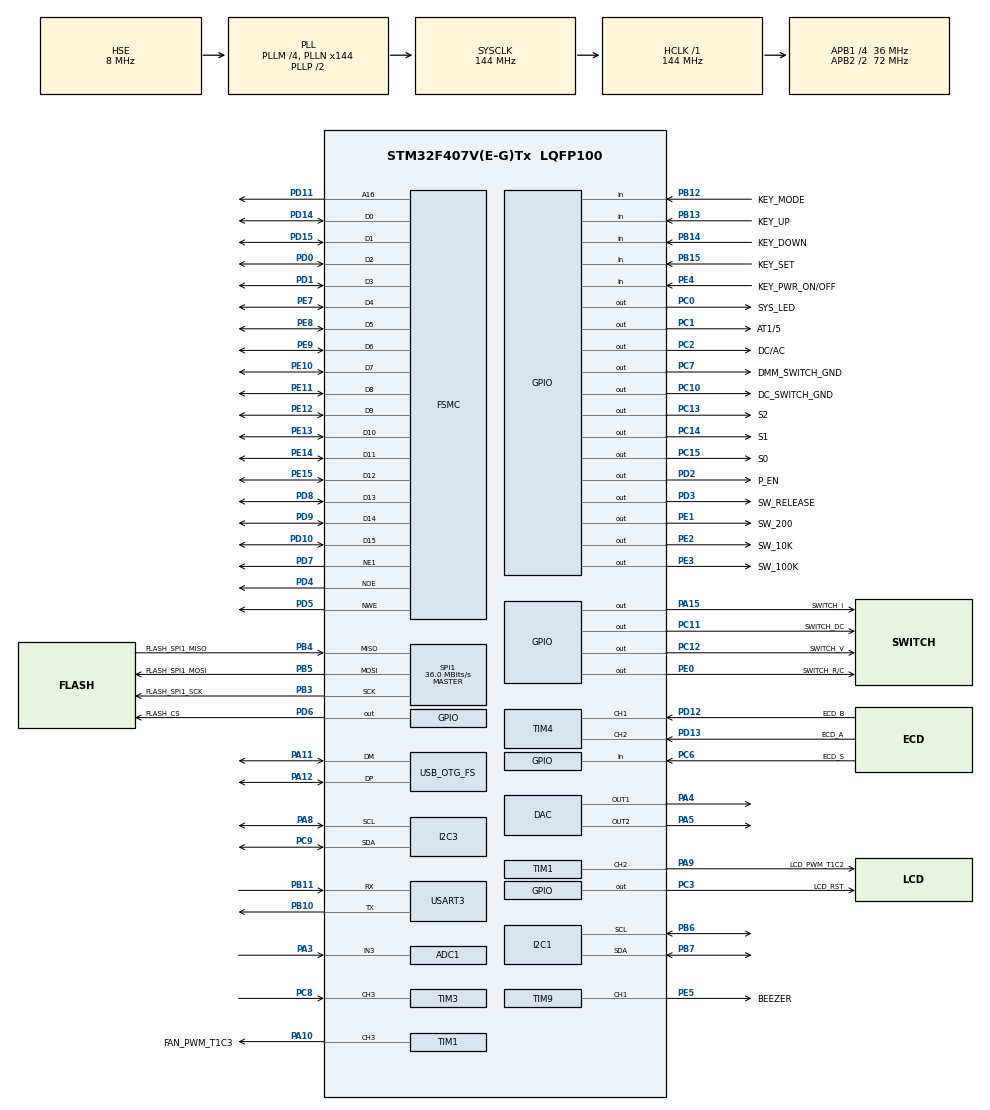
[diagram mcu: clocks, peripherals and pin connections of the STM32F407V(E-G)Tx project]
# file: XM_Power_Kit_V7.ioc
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ADC1.Channel-4\#ChannelRegularConversion=ADC_CHANNEL_3
ADC1.DMAContinuousRequests=ENABLE
ADC1.EOCSelection=ADC_EOC_SINGLE_CONV
ADC1.ExternalTrigConv=ADC_EXTERNALTRIGCONV_T8_TRGO
ADC1.NbrOfConversion=1
ADC1.NbrOfConversionFlag=1
ADC1.Rank-4\#ChannelRegularConversion=1
ADC1.Resolution=ADC_RESOLUTION_8B
ADC1.SamplingTime-4\#ChannelRegularConversion=ADC_SAMPLETIME_3CYCLES
ADC1.ScanConvMode=DISABLE
ADC1.master=1
DAC.DAC_Trigger=DAC_TRIGGER_T7_TRGO
DAC.WaveGeneration=DISABLE
Dma.ADC1.3.Direction=DMA_PERIPH_TO_MEMORY
Dma.ADC1.3.FIFOMode=DMA_FIFOMODE_DISABLE
Dma.ADC1.3.Instance=DMA2_Stream4
Dma.ADC1.3.MemDataAlignment=DMA_MDATAALIGN_BYTE
Dma.ADC1.3.MemInc=DMA_MINC_ENABLE
Dma.ADC1.3.Mode=DMA_CIRCULAR
Dma.ADC1.3.PeriphDataAlignment=DMA_PDATAALIGN_BYTE
Dma.ADC1.3.PeriphInc=DMA_PINC_DISABLE
Dma.ADC1.3.Priority=DMA_PRIORITY_HIGH
Dma.DAC1.4.Direction=DMA_MEMORY_TO_PERIPH
Dma.DAC1.4.FIFOMode=DMA_FIFOMODE_DISABLE
Dma.DAC1.4.Instance=DMA1_Stream5
Dma.DAC1.4.MemDataAlignment=DMA_MDATAALIGN_HALFWORD
Dma.DAC1.4.MemInc=DMA_MINC_ENABLE
Dma.DAC1.4.Mode=DMA_CIRCULAR
Dma.DAC1.4.PeriphDataAlignment=DMA_PDATAALIGN_HALFWORD
Dma.DAC1.4.PeriphInc=DMA_PINC_DISABLE
Dma.DAC1.4.Priority=DMA_PRIORITY_MEDIUM
Dma.MEMTOMEM.2.Direction=DMA_MEMORY_TO_MEMORY
Dma.MEMTOMEM.2.FIFOMode=DMA_FIFOMODE_ENABLE
Dma.MEMTOMEM.2.FIFOThreshold=DMA_FIFO_THRESHOLD_FULL
Dma.MEMTOMEM.2.Instance=DMA2_Stream6
Dma.MEMTOMEM.2.MemBurst=DMA_MBURST_SINGLE
Dma.MEMTOMEM.2.MemDataAlignment=DMA_MDATAALIGN_HALFWORD
Dma.MEMTOMEM.2.MemInc=DMA_MINC_ENABLE
Dma.MEMTOMEM.2.Mode=DMA_NORMAL
Dma.MEMTOMEM.2.PeriphBurst=DMA_PBURST_SINGLE
Dma.MEMTOMEM.2.PeriphDataAlignment=DMA_PDATAALIGN_HALFWORD
Dma.MEMTOMEM.2.PeriphInc=DMA_PINC_ENABLE
Dma.MEMTOMEM.2.Priority=DMA_PRIORITY_LOW
Dma.Request0=SPI1_RX
Dma.Request1=SPI1_TX
Dma.Request2=MEMTOMEM
Dma.Request3=ADC1
Dma.Request4=DAC1
Dma.SPI1_RX.0.Direction=DMA_PERIPH_TO_MEMORY
Dma.SPI1_RX.0.FIFOMode=DMA_FIFOMODE_DISABLE
Dma.SPI1_RX.0.Instance=DMA2_Stream0
Dma.SPI1_RX.0.MemDataAlignment=DMA_MDATAALIGN_BYTE
Dma.SPI1_RX.0.MemInc=DMA_MINC_ENABLE
Dma.SPI1_RX.0.Mode=DMA_NORMAL
Dma.SPI1_RX.0.PeriphDataAlignment=DMA_PDATAALIGN_BYTE
Dma.SPI1_RX.0.PeriphInc=DMA_PINC_DISABLE
Dma.SPI1_RX.0.Priority=DMA_PRIORITY_MEDIUM
Dma.SPI1_TX.1.Direction=DMA_MEMORY_TO_PERIPH
Dma.SPI1_TX.1.FIFOMode=DMA_FIFOMODE_DISABLE
Dma.SPI1_TX.1.Instance=DMA2_Stream3
Dma.SPI1_TX.1.MemDataAlignment=DMA_MDATAALIGN_BYTE
Dma.SPI1_TX.1.MemInc=DMA_MINC_ENABLE
Dma.SPI1_TX.1.Mode=DMA_NORMAL
Dma.SPI1_TX.1.PeriphDataAlignment=DMA_PDATAALIGN_BYTE
Dma.SPI1_TX.1.PeriphInc=DMA_PINC_DISABLE
Dma.SPI1_TX.1.Priority=DMA_PRIORITY_MEDIUM
FREERTOS.BinarySemaphores01=FLASH_TX_Cplt_Sem,Dynamic,NULL,Depleted;FLASH_RX_Cplt_Sem,Dynamic,NULL,Depleted;LCD_DMA_Cplt_Sem,Dynamic,NULL,Depleted
FREERTOS.INCLUDE_uxTaskGetStackHighWaterMark2=1
FREERTOS.INCLUDE_xTaskGetHandle=1
FREERTOS.Mutexes01=IIC1_Mutex,Dynamic,NULL,Available;IIC3_Mutex,Dynamic,NULL,Available;Flash_Mutex,Dynamic,NULL,Available
FREERTOS.Queues01=AppSwitchQueue,1,AppListType,0,Dynamic,NULL,NULL;LcdMsgQueue,48,refresh_msg_t*,0,Dynamic,NULL,NULL;KeyEventQueue,8,KeyEventMsg_t,0,Dynamic,NULL,NULL;BeezerQueue,8,uint16_t,0,Dynamic,NULL,NULL;SerialReqQueue,3,ProtoFrame_t,0,Dynamic,NULL,NULL
FREERTOS.Tasks01=InitTask,55,384,Start_InitTask,As weak,NULL,Dynamic,NULL,NULL;SensorTask,48,192,Start_SensorTask,As external,NULL,Dynamic,NULL,NULL;LcdFlushTask,41,512,Start_LcdFlushTask,As external,NULL,Dynamic,NULL,NULL;PageSelectTask,40,512,Start_PageSelectTask,As external,NULL,Dynamic,NULL,NULL;LvglCoreTask,24,768,Start_LvglCoreTask,As external,NULL,Dynamic,NULL,NULL;DpsCoreTask,24,512,Start_DpsCoreTask,As external,NULL,Dynamic,NULL,NULL;IndevDetectTask,28,128,Start_IndevDetectTask,As external,NULL,Dynamic,NULL,NULL;PIDTask,25,256,Start_PIDTask,As external,NULL,Dynamic,NULL,NULL;CalibrateTask,24,512,Start_CalibrateTask,As external,NULL,Dynamic,NULL,NULL;AwgTask,24,256,Start_AwgTask,As external,NULL,Dynamic,NULL,NULL;DmmCoreTask,24,512,Start_DmmCoreTask,As external,NULL,Dynamic,NULL,NULL;DsoCoreTask,24,512,Start_DsoCoreTask,As external,NULL,Dynamic,NULL,NULL;UserCoreTask,24,512,Start_UserCoreTask,As external,NULL,Dynamic,NULL,NULL;SerialCoreTask,49,384,Start_SerialCoreTask,As external,NULL,Dynamic,NULL,NULL
FREERTOS.configCHECK_FOR_STACK_OVERFLOW=2
FREERTOS.configENABLE_FPU=1
FREERTOS.configGENERATE_RUN_TIME_STATS=1
FREERTOS.configRECORD_STACK_HIGH_ADDRESS=1
FREERTOS.configTOTAL_HEAP_SIZE=32768
FSMC.AddressSetupTime1=5
FSMC.BusTurnAroundDuration1=15
FSMC.DataSetupTime1=5
FSMC.ExtendedMode1=FSMC_EXTENDED_MODE_DISABLE
I2C1.I2C_Mode=I2C_Fast
I2C3.I2C_Mode=I2C_Fast
Mcu.Family=STM32F4
Mcu.Name=STM32F407V(E-G)Tx
Mcu.Package=LQFP100
NVIC.DMA2_Stream0_IRQn=true\:8\:0\:true\:false\:true\:true\:false\:true\:true
NVIC.DMA2_Stream3_IRQn=true\:8\:0\:true\:false\:true\:true\:false\:true\:true
NVIC.DMA2_Stream4_IRQn=true\:5\:0\:false\:false\:true\:true\:true\:true\:true
NVIC.DMA2_Stream6_IRQn=true\:7\:0\:true\:false\:true\:false\:true\:true\:true
NVIC.OTG_FS_IRQn=true\:10\:0\:true\:false\:true\:true\:false\:true\:true
NVIC.PriorityGroup=NVIC_PRIORITYGROUP_4
NVIC.TIM1_TRG_COM_TIM11_IRQn=true\:5\:0\:false\:false\:true\:true\:true\:true\:true
NVIC.TIM3_IRQn=true\:5\:0\:false\:false\:true\:true\:true\:true\:true
NVIC.TIM6_DAC_IRQn=true\:15\:0\:false\:false\:true\:false\:false\:true\:true
NVIC.TimeBase=TIM6_DAC_IRQn
NVIC.TimeBaseIP=TIM6
PA10.GPIO_Label=FAN_PWM_T1C3
PA10.Signal=S_TIM1_CH3
PA11.Mode=Device_Only
PA11.Signal=USB_OTG_FS_DM
PA12.Mode=Device_Only
PA12.Signal=USB_OTG_FS_DP
PA13.Mode=Serial_Wire
PA13.Signal=SYS_JTMS-SWDIO
PA14.Mode=Serial_Wire
PA14.Signal=SYS_JTCK-SWCLK
PA15.GPIO_Label=SWITCH_I
PA15.Signal=GPIO_Output
PA3.Signal=ADCx_IN3
PA4.Signal=COMP_DAC1_group
PA5.Signal=COMP_DAC2_group
PA8.Mode=I2C
PA8.Signal=I2C3_SCL
PA9.GPIO_Label=LCD_PWM_T1C2
PA9.Signal=S_TIM1_CH2
PB10.Mode=Asynchronous
PB10.Signal=USART3_TX
PB11.Mode=Asynchronous
PB11.Signal=USART3_RX
PB12.GPIO_Label=KEY_MODE
PB12.Signal=GPIO_Input
PB13.GPIO_Label=KEY_UP
PB13.Signal=GPIO_Input
PB14.GPIO_Label=KEY_DOWN
PB14.Signal=GPIO_Input
PB15.GPIO_Label=KEY_SET
PB15.Signal=GPIO_Input
PB3.GPIO_Label=FLASH_SPI1_SCK
PB3.Mode=Full_Duplex_Master
PB3.Signal=SPI1_SCK
PB4.GPIO_Label=FLASH_SPI1_MISO
PB4.Mode=Full_Duplex_Master
PB4.Signal=SPI1_MISO
PB5.GPIO_Label=FLASH_SPI1_MOSI
PB5.Mode=Full_Duplex_Master
PB5.Signal=SPI1_MOSI
PB6.Mode=I2C
PB6.Signal=I2C1_SCL
PB7.Mode=I2C
PB7.Signal=I2C1_SDA
PC0.GPIO_Label=SYS_LED
PC0.PinState=GPIO_PIN_SET
PC0.Signal=GPIO_Output
PC1.GPIO_Label=AT1/5
PC1.Signal=GPIO_Output
PC10.GPIO_Label=DC_SWITCH_GND
PC10.Signal=GPIO_Output
PC11.GPIO_Label=SWITCH_DC
PC11.PinState=GPIO_PIN_SET
PC11.Signal=GPIO_Output
PC12.GPIO_Label=SWITCH_V
PC12.Signal=GPIO_Output
PC13-ANTI_TAMP.GPIO_Label=S2
PC13-ANTI_TAMP.PinState=GPIO_PIN_SET
PC13-ANTI_TAMP.Signal=GPIO_Output
PC14-OSC32_IN.GPIO_Label=S1
PC14-OSC32_IN.Signal=GPIO_Output
PC15-OSC32_OUT.GPIO_Label=S0
PC15-OSC32_OUT.Signal=GPIO_Output
PC2.GPIO_Label=DC/AC
PC2.PinState=GPIO_PIN_SET
PC2.Signal=GPIO_Output
PC3.GPIO_Label=LCD_RST
PC3.Signal=GPIO_Output
PC6.GPIO_Label=ECD_S
PC6.Signal=GPIO_Input
PC7.GPIO_Label=DMM_SWITCH_GND
PC7.Signal=GPIO_Output
PC8.Signal=S_TIM3_CH3
PC9.Mode=I2C
PC9.Signal=I2C3_SDA
PD0.Mode=16b-d1
PD0.Signal=FSMC_D2
PD1.Mode=16b-d1
PD1.Signal=FSMC_D3
PD10.Mode=16b-d1
PD10.Signal=FSMC_D15
PD11.Mode=A16_1
PD11.Signal=FSMC_A16
PD12.GPIO_Label=ECD_B
PD12.Signal=S_TIM4_CH1
PD13.GPIO_Label=ECD_A
PD13.Signal=S_TIM4_CH2
PD14.Mode=16b-d1
PD14.Signal=FSMC_D0
PD15.Mode=16b-d1
PD15.Signal=FSMC_D1
PD2.GPIO_Label=P_EN
PD2.Signal=GPIO_Output
PD3.GPIO_Label=SW_RELEASE
PD3.Signal=GPIO_Output
PD4.Mode=Lcd1
PD4.Signal=FSMC_NOE
PD5.Mode=Lcd1
PD5.Signal=FSMC_NWE
PD6.GPIO_Label=FLASH_CS
PD6.PinState=GPIO_PIN_SET
PD6.Signal=GPIO_Output
PD7.Mode=NorPsramChipSelect1_1
PD7.Signal=FSMC_NE1
PD8.Mode=16b-d1
PD8.Signal=FSMC_D13
PD9.Mode=16b-d1
PD9.Signal=FSMC_D14
PE0.GPIO_Label=SWITCH_R/C
PE0.Signal=GPIO_Output
PE1.GPIO_Label=SW_200
PE1.PinState=GPIO_PIN_SET
PE1.Signal=GPIO_Output
PE10.Mode=16b-d1
PE10.Signal=FSMC_D7
PE11.Mode=16b-d1
PE11.Signal=FSMC_D8
PE12.Mode=16b-d1
PE12.Signal=FSMC_D9
PE13.Mode=16b-d1
PE13.Signal=FSMC_D10
PE14.Mode=16b-d1
PE14.Signal=FSMC_D11
PE15.Mode=16b-d1
PE15.Signal=FSMC_D12
PE2.GPIO_Label=SW_10K
PE2.PinState=GPIO_PIN_SET
PE2.Signal=GPIO_Output
PE3.GPIO_Label=SW_100K
PE3.PinState=GPIO_PIN_SET
PE3.Signal=GPIO_Output
PE4.GPIO_Label=KEY_PWR_ON/OFF
PE4.Signal=GPIO_Input
PE5.GPIO_Label=BEEZER
PE5.Signal=S_TIM9_CH1
PE7.Mode=16b-d1
PE7.Signal=FSMC_D4
PE8.Mode=16b-d1
PE8.Signal=FSMC_D5
PE9.Mode=16b-d1
PE9.Signal=FSMC_D6
PH0-OSC_IN.Mode=HSE-External-Oscillator
PH0-OSC_IN.Signal=RCC_OSC_IN
PH1-OSC_OUT.Mode=HSE-External-Oscillator
PH1-OSC_OUT.Signal=RCC_OSC_OUT
ProjectManager.HeapSize=0x1800
ProjectManager.StackSize=0x1000
ProjectManager.TargetToolchain=CMake
RCC.48MHZClocksFreq_Value=48000000
RCC.AHBFreq_Value=144000000
RCC.APB1CLKDivider=RCC_HCLK_DIV4
RCC.APB1Freq_Value=36000000
RCC.APB1TimFreq_Value=72000000
RCC.APB2CLKDivider=RCC_HCLK_DIV2
RCC.APB2Freq_Value=72000000
RCC.APB2TimFreq_Value=144000000
RCC.CortexFreq_Value=144000000
RCC.HCLKFreq_Value=144000000
RCC.HSE_VALUE=8000000
RCC.HSI_VALUE=16000000
RCC.LSE_VALUE=32768
RCC.PLLM=4
RCC.PLLN=144
RCC.PLLQ=6
RCC.SYSCLKFreq_VALUE=144000000
RCC.SYSCLKSource=RCC_SYSCLKSOURCE_PLLCLK
RCC.VCOOutputFreq_Value=288000000
SH.ADCx_IN3.0=ADC1_IN3,IN3
SH.COMP_DAC1_group.0=DAC_OUT1,DAC_OUT1
SH.COMP_DAC2_group.0=DAC_OUT2,DAC_OUT2
SH.S_TIM1_CH2.0=TIM1_CH2,PWM Generation2 CH2
SH.S_TIM1_CH3.0=TIM1_CH3,PWM Generation3 CH3
SH.S_TIM3_CH3.0=TIM3_CH3,Input_Capture3_from_TI3
SH.S_TIM4_CH1.0=TIM4_CH1,Encoder_Interface
SH.S_TIM4_CH2.0=TIM4_CH2,Encoder_Interface
SH.S_TIM9_CH1.0=TIM9_CH1,PWM Generation1 CH1
SPI1.BaudRatePrescaler=SPI_BAUDRATEPRESCALER_2
SPI1.CalculateBaudRate=36.0 MBits/s
SPI1.Direction=SPI_DIRECTION_2LINES
SPI1.Mode=SPI_MODE_MASTER
SPI1.VirtualType=VM_MASTER
TIM1.Channel-PWM\ Generation2\ CH2=TIM_CHANNEL_2
TIM1.Channel-PWM\ Generation3\ CH3=TIM_CHANNEL_3
TIM1.OCFastMode_PWM-PWM\ Generation3\ CH3=TIM_OCFAST_ENABLE
TIM1.Period=1999
TIM1.Prescaler=143
TIM1.Pulse-PWM\ Generation2\ CH2=4999
TIM1.Pulse-PWM\ Generation3\ CH3=0
TIM3.Channel-Input_Capture3_from_TI3=TIM_CHANNEL_3
TIM3.ICFilter_CH3=4
TIM4.EncoderMode=TIM_ENCODERMODE_TI12
TIM4.IC1Filter=3
TIM4.IC1Prescaler=TIM_ICPSC_DIV2
TIM4.IC2Filter=3
TIM4.IC2Prescaler=TIM_ICPSC_DIV2
TIM7.TIM_MasterOutputTrigger=TIM_TRGO_UPDATE
TIM8.Period=15 - 1
TIM8.Prescaler=150 - 1
TIM8.TIM_MasterOutputTrigger=TIM_TRGO_UPDATE
TIM9.Channel-PWM\ Generation1\ CH1=TIM_CHANNEL_1
TIM9.Period=99
TIM9.Prescaler=359
TIM9.Pulse-PWM\ Generation1\ CH1=49
USART3.VirtualMode=VM_ASYNC
USB_DEVICE.APP_RX_DATA_SIZE-CDC_FS=512
USB_DEVICE.APP_TX_DATA_SIZE-CDC_FS=512
USB_DEVICE.CLASS_NAME_FS=CDC
USB_DEVICE.VirtualMode-CDC_FS=Cdc
USB_DEVICE.VirtualModeFS=Cdc_FS
USB_OTG_FS.VirtualMode=Device_Only
VP_FREERTOS_VS_CMSIS_V2.Mode=CMSIS_V2
VP_SYS_VS_tim6.Mode=TIM6
VP_TIM11_VS_ClockSourceINT.Mode=Enable_Timer
VP_TIM3_VS_ClockSourceINT.Mode=Internal
VP_TIM7_VS_ClockSourceINT.Mode=Enable_Timer
VP_TIM8_VS_ClockSourceINT.Mode=Internal
VP_USB_DEVICE_VS_USB_DEVICE_CDC_FS.Mode=CDC_FS
board=custom

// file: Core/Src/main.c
/* USER CODE BEGIN Header */
/**
  ******************************************************************************
  * @file           : main.c
  * @brief          : Main program body
  ******************************************************************************
  * @attention
  *
  * Copyright (c) 2026 STMicroelectronics.
  * All rights reserved.
  *
  * This software is licensed under terms that can be found in the LICENSE file
  * in the root directory of this software component.
  * If no LICENSE file comes with this software, it is provided AS-IS.
  *
  ******************************************************************************
  */
/* USER CODE END Header */
#include "main.h"
#include "cmsis_os.h"
#include "adc.h"
#include "dac.h"
#include "dma.h"
#include "i2c.h"
#include "spi.h"
#include "tim.h"
#include "usart.h"
#include "usb_device.h"
#include "gpio.h"
#include "fsmc.h"

/* USER CODE BEGIN Includes */
#include <stdarg.h>
#include "ff.h"
#include "Flash.h"
#include "UserTask.h"
#include "SwitchManager.h"

/* USER CODE END Includes */

/* USER CODE BEGIN PTD */
char Sys_Version[30] = SYS_VERSION_CODE;
/* USER CODE END PTD */

void SystemClock_Config(void);
void MX_FREERTOS_Init(void);

int main(void)
{

  /* USER CODE BEGIN 1 */
  /* OTA：应用链接在 0x08008000（前面 32K 是 bootloader），向量表必须跟着搬家，
     且必须在 HAL_Init()（会启动 TIM6 中断）之前完成。 */
  SCB->VTOR = 0x08010000U;
  /* USER CODE END 1 */

  /* MCU Configuration--------------------------------------------------------*/

  /* Reset of all peripherals, Initializes the Flash interface and the Systick. */
  HAL_Init();

  /* Configure the system clock */
  SystemClock_Config();

  /* Initialize all configured peripherals */
  MX_GPIO_Init();
  MX_DMA_Init();
  MX_SPI1_Init();
  MX_USART3_UART_Init();
  MX_FSMC_Init();
  MX_I2C1_Init();
  MX_I2C3_Init();
  MX_TIM1_Init();
  MX_TIM4_Init();
  MX_TIM7_Init();
  MX_TIM8_Init();
  MX_TIM9_Init();
  MX_ADC1_Init();
  MX_DAC_Init();
  MX_TIM11_Init();
  MX_TIM3_Init();

  /* Init scheduler */
  osKernelInitialize();  /* Call init function for freertos objects (in cmsis_os2.c) */
  MX_FREERTOS_Init();

  /* Start scheduler */
  osKernelStart();

  /* We should never get here as control is now taken by the scheduler */

  /* Infinite loop */
  while (1)
  {

  }
}

void SystemClock_Config(void)
{
  RCC_OscInitTypeDef RCC_OscInitStruct = {0};
  RCC_ClkInitTypeDef RCC_ClkInitStruct = {0};

  /** Configure the main internal regulator output voltage
  */
  __HAL_RCC_PWR_CLK_ENABLE();
  __HAL_PWR_VOLTAGESCALING_CONFIG(PWR_REGULATOR_VOLTAGE_SCALE1);

  /** Initializes the RCC Oscillators according to the specified parameters
  * in the RCC_OscInitTypeDef structure.
  */
  RCC_OscInitStruct.OscillatorType = RCC_OSCILLATORTYPE_HSE;
  RCC_OscInitStruct.HSEState = RCC_HSE_ON;
  RCC_OscInitStruct.PLL.PLLState = RCC_PLL_ON;
  RCC_OscInitStruct.PLL.PLLSource = RCC_PLLSOURCE_HSE;
  RCC_OscInitStruct.PLL.PLLM = 4;
  RCC_OscInitStruct.PLL.PLLN = 144;
  RCC_OscInitStruct.PLL.PLLP = RCC_PLLP_DIV2;
  RCC_OscInitStruct.PLL.PLLQ = 6;
  if (HAL_RCC_OscConfig(&RCC_OscInitStruct) != HAL_OK)
  {
    Error_Handler();
  }

  /** Initializes the CPU, AHB and APB buses clocks
  */
  RCC_ClkInitStruct.ClockType = RCC_CLOCKTYPE_HCLK|RCC_CLOCKTYPE_SYSCLK
                              |RCC_CLOCKTYPE_PCLK1|RCC_CLOCKTYPE_PCLK2;
  RCC_ClkInitStruct.SYSCLKSource = RCC_SYSCLKSOURCE_PLLCLK;
  RCC_ClkInitStruct.AHBCLKDivider = RCC_SYSCLK_DIV1;
  RCC_ClkInitStruct.APB1CLKDivider = RCC_HCLK_DIV4;
  RCC_ClkInitStruct.APB2CLKDivider = RCC_HCLK_DIV2;

  if (HAL_RCC_ClockConfig(&RCC_ClkInitStruct, FLASH_LATENCY_4) != HAL_OK)
  {
    Error_Handler();
  }
}

void HAL_TIM_PeriodElapsedCallback(TIM_HandleTypeDef *htim)
{
  if (htim->Instance == TIM6)
  {
    HAL_IncTick();
    PWM_BrightnessService();        // 背光渐变（1ms 时基驱动）
  }
}

void Error_Handler(void)
{
  /* USER CODE BEGIN Error_Handler_Debug */
  /* User can add his own implementation to report the HAL error return state */
  //__disable_irq();
  while (1)
  {
    HAL_GPIO_TogglePin(GPIOC, GPIO_PIN_0);
    HAL_Delay(100);
  }
  /* USER CODE END Error_Handler_Debug */
}

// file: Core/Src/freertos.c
/* USER CODE BEGIN Header */
/**
  ******************************************************************************
  * File Name          : freertos.c
  * Description        : Code for freertos applications
  ******************************************************************************
  * @attention
  *
  * Copyright (c) 2026 STMicroelectronics.
  * All rights reserved.
  *
  * This software is licensed under terms that can be found in the LICENSE file
  * in the root directory of this software component.
  * If no LICENSE file comes with this software, it is provided AS-IS.
  *
  ******************************************************************************
  */
/* USER CODE END Header */

#include "FreeRTOS.h"
#include "task.h"
#include "main.h"
#include "cmsis_os.h"

/* USER CODE BEGIN Includes */
#include <stdio.h>

#include "ff.h"
#include "Flash.h"
#include "i2c.h"
#include "INA226_Driver.h"
#include "Keys.h"
#include "SerialCoreTask.h"
#include "UserTask.h"
#include "lcd_draw_api.h"
#include "ST7789.h"
#include "SwitchManager.h"
#include "TMP102.h"
/* USER CODE END Includes */

/* USER CODE BEGIN PD */
uint8_t ucHeap[ configTOTAL_HEAP_SIZE ] __attribute__((section(".ccmram_rtos"), aligned(4)));

/* USER CODE END PD */

/* Definitions for InitTask */
osThreadId_t InitTaskHandle;
const osThreadAttr_t InitTask_attributes = {
  .name = "InitTask",
  .stack_size = 384 * 4,
  .priority = (osPriority_t) osPriorityRealtime7,
};
/* Definitions for SensorTask */
osThreadId_t SensorTaskHandle;
const osThreadAttr_t SensorTask_attributes = {
  .name = "SensorTask",
  .stack_size = 192 * 4,
  .priority = (osPriority_t) osPriorityRealtime,
};
/* Definitions for LcdFlushTask */
osThreadId_t LcdFlushTaskHandle;
const osThreadAttr_t LcdFlushTask_attributes = {
  .name = "LcdFlushTask",
  .stack_size = 512 * 4,
  .priority = (osPriority_t) osPriorityHigh1,
};
/* Definitions for PageSelectTask */
osThreadId_t PageSelectTaskHandle;
const osThreadAttr_t PageSelectTask_attributes = {
  .name = "PageSelectTask",
  .stack_size = 512 * 4,
  .priority = (osPriority_t) osPriorityHigh,
};
/* Definitions for GuiTask */
osThreadId_t GuiTaskHandle;
const osThreadAttr_t GuiTask_attributes = {
  .name = "GuiTask",
  .stack_size = 512 * 4,
  .priority = (osPriority_t) osPriorityNormal,
};
/* Definitions for DpsCoreTask */
osThreadId_t DpsCoreTaskHandle;
const osThreadAttr_t DpsCoreTask_attributes = {
  .name = "DpsCoreTask",
  .stack_size = 512 * 4,
  .priority = (osPriority_t) osPriorityNormal,
};
/* Definitions for IndevDetectTask */
osThreadId_t IndevDetectTaskHandle;
const osThreadAttr_t IndevDetectTask_attributes = {
  .name = "IndevDetectTask",
  .stack_size = 128 * 4,
  .priority = (osPriority_t) osPriorityNormal4,
};
/* Definitions for PIDTask */
osThreadId_t PIDTaskHandle;
const osThreadAttr_t PIDTask_attributes = {
  .name = "PIDTask",
  .stack_size = 256 * 4,
  .priority = (osPriority_t) osPriorityNormal1,
};
/* Definitions for CalibrateTask */
osThreadId_t CalibrateTaskHandle;
const osThreadAttr_t CalibrateTask_attributes = {
  .name = "CalibrateTask",
  .stack_size = 512 * 4,
  .priority = (osPriority_t) osPriorityNormal,
};
/* Definitions for AwgTask */
osThreadId_t AwgTaskHandle;
const osThreadAttr_t AwgTask_attributes = {
  .name = "AwgTask",
  .stack_size = 256 * 4,
  .priority = (osPriority_t) osPriorityNormal,
};
/* Definitions for DmmCoreTask */
osThreadId_t DmmCoreTaskHandle;
const osThreadAttr_t DmmCoreTask_attributes = {
  .name = "DmmCoreTask",
  .stack_size = 512 * 4,
  .priority = (osPriority_t) osPriorityNormal,
};
/* Definitions for PdTask */
osThreadId_t PdTaskHandle;
const osThreadAttr_t PdTask_attributes = {
  .name = "PdTask",
  .stack_size = 512 * 4,
  .priority = (osPriority_t) osPriorityNormal,
};
/* Definitions for DsoCoreTask */
osThreadId_t DsoCoreTaskHandle;
const osThreadAttr_t DsoCoreTask_attributes = {
  .name = "DsoCoreTask",
  .stack_size = 512 * 4,
  .priority = (osPriority_t) osPriorityNormal,
};
/* Definitions for SerialCoreTask */
osThreadId_t SerialCoreTaskHandle;
const osThreadAttr_t SerialCoreTask_attributes = {
  .name = "SerialCoreTask",
  .stack_size = 384 * 4,
  .priority = (osPriority_t) osPriorityRealtime1,
};
/* Definitions for AppSwitchQueue */
osMessageQueueId_t AppSwitchQueueHandle;
const osMessageQueueAttr_t AppSwitchQueue_attributes = {
  .name = "AppSwitchQueue"
};
/* Definitions for LcdMsgQueue */
osMessageQueueId_t LcdMsgQueueHandle;
const osMessageQueueAttr_t LcdMsgQueue_attributes = {
  .name = "LcdMsgQueue"
};
/* Definitions for KeyEventQueue */
osMessageQueueId_t KeyEventQueueHandle;
const osMessageQueueAttr_t KeyEventQueue_attributes = {
  .name = "KeyEventQueue"
};
/* Definitions for BeezerQueue */
osMessageQueueId_t BeezerQueueHandle;
const osMessageQueueAttr_t BeezerQueue_attributes = {
  .name = "BeezerQueue"
};
/* Definitions for SerialReqQueue */
osMessageQueueId_t SerialReqQueueHandle;
const osMessageQueueAttr_t SerialReqQueue_attributes = {
  .name = "SerialReqQueue"
};
/* Definitions for IIC1_Mutex */
osMutexId_t IIC1_MutexHandle;
const osMutexAttr_t IIC1_Mutex_attributes = {
  .name = "IIC1_Mutex"
};
/* Definitions for IIC3_Mutex */
osMutexId_t IIC3_MutexHandle;
const osMutexAttr_t IIC3_Mutex_attributes = {
  .name = "IIC3_Mutex"
};
/* Definitions for Flash_Mutex */
osMutexId_t Flash_MutexHandle;
const osMutexAttr_t Flash_Mutex_attributes = {
  .name = "Flash_Mutex"
};
/* Definitions for FLASH_TX_Cplt_Sem */
osSemaphoreId_t FLASH_TX_Cplt_SemHandle;
const osSemaphoreAttr_t FLASH_TX_Cplt_Sem_attributes = {
  .name = "FLASH_TX_Cplt_Sem"
};
/* Definitions for FLASH_RX_Cplt_Sem */
osSemaphoreId_t FLASH_RX_Cplt_SemHandle;
const osSemaphoreAttr_t FLASH_RX_Cplt_Sem_attributes = {
  .name = "FLASH_RX_Cplt_Sem"
};
/* Definitions for LCD_DMA_Cplt_Sem */
osSemaphoreId_t LCD_DMA_Cplt_SemHandle;
const osSemaphoreAttr_t LCD_DMA_Cplt_Sem_attributes = {
  .name = "LCD_DMA_Cplt_Sem"
};

void Start_InitTask(void *argument);
extern void Start_SensorTask(void *argument);
extern void Start_LcdFlushTask(void *argument);
extern void Start_PageSelectTask(void *argument);
extern void Start_GuiTask(void *argument);
extern void Start_DpsCoreTask(void *argument);
extern void Start_IndevDetectTask(void *argument);
extern void Start_PIDTask(void *argument);
extern void Start_CalibrateTask(void *argument);
extern void Start_AwgTask(void *argument);
extern void Start_DmmCoreTask(void *argument);
extern void Start_PdTask(void *argument);
extern void Start_DsoCoreTask(void *argument);
extern void Start_SerialCoreTask(void *argument);

extern void MX_USB_DEVICE_Init(void);
void MX_FREERTOS_Init(void); /* (MISRA C 2004 rule 8.1) */

/* Hook prototypes */
void configureTimerForRunTimeStats(void);
unsigned long getRunTimeCounterValue(void);
void vApplicationStackOverflowHook(xTaskHandle xTask, signed char *pcTaskName);

/* USER CODE BEGIN 1 */
/* Functions needed when configGENERATE_RUN_TIME_STATS is on */
__weak void configureTimerForRunTimeStats(void)
{

}

__weak unsigned long getRunTimeCounterValue(void)
{
return 0;
}
/* USER CODE END 1 */

/* USER CODE BEGIN 4 */
void vApplicationStackOverflowHook(xTaskHandle xTask, signed char *pcTaskName)
{
   /* Run time stack overflow checking is performed if
   configCHECK_FOR_STACK_OVERFLOW is defined to 1 or 2. This hook function is
   called if a stack overflow is detected. */
  while (1) {
    SysLed_ON();
    HAL_Delay(100);
    SysLed_OFF();
    HAL_Delay(100);
  }
}
/* USER CODE END 4 */

void MX_FREERTOS_Init(void) {
  /* Create the mutex(es) */
  /* creation of IIC1_Mutex */
  IIC1_MutexHandle = osMutexNew(&IIC1_Mutex_attributes);

  /* creation of IIC3_Mutex */
  IIC3_MutexHandle = osMutexNew(&IIC3_Mutex_attributes);

  /* creation of Flash_Mutex */
  Flash_MutexHandle = osMutexNew(&Flash_Mutex_attributes);

  /* Create the semaphores(s) */
  /* creation of FLASH_TX_Cplt_Sem */
  FLASH_TX_Cplt_SemHandle = osSemaphoreNew(1, 0, &FLASH_TX_Cplt_Sem_attributes);

  /* creation of FLASH_RX_Cplt_Sem */
  FLASH_RX_Cplt_SemHandle = osSemaphoreNew(1, 0, &FLASH_RX_Cplt_Sem_attributes);

  /* creation of LCD_DMA_Cplt_Sem */
  LCD_DMA_Cplt_SemHandle = osSemaphoreNew(1, 0, &LCD_DMA_Cplt_Sem_attributes);

  /* Create the queue(s) */
  /* creation of AppSwitchQueue */
  AppSwitchQueueHandle = osMessageQueueNew (1, sizeof(AppListType), &AppSwitchQueue_attributes);

  /* creation of LcdMsgQueue */
  LcdMsgQueueHandle = osMessageQueueNew (48, sizeof(refresh_msg_t*), &LcdMsgQueue_attributes);

  /* creation of KeyEventQueue */
  KeyEventQueueHandle = osMessageQueueNew (8, sizeof(KeyEventMsg_t), &KeyEventQueue_attributes);

  /* creation of BeezerQueue */
  BeezerQueueHandle = osMessageQueueNew (8, sizeof(uint16_t), &BeezerQueue_attributes);

  /* creation of SerialReqQueue（上位机请求帧，深度 3） */
  SerialReqQueueHandle = osMessageQueueNew (3, sizeof(ProtoFrame_t), &SerialReqQueue_attributes);

  /* USER CODE BEGIN RTOS_QUEUES */
  /* add queues, ... */
  // 初始化静态绘图命令池（必须在 osKernelStart() 之前完成）
  LcdDraw_InitPool();
  /* USER CODE END RTOS_QUEUES */

  /* Create the thread(s) */
  /* creation of InitTask */
  InitTaskHandle = osThreadNew(Start_InitTask, NULL, &InitTask_attributes);

  /* creation of SensorTask */
  SensorTaskHandle = osThreadNew(Start_SensorTask, NULL, &SensorTask_attributes);

  /* creation of LcdFlushTask */
  LcdFlushTaskHandle = osThreadNew(Start_LcdFlushTask, NULL, &LcdFlushTask_attributes);

  /* creation of PageSelectTask */
  PageSelectTaskHandle = osThreadNew(Start_PageSelectTask, NULL, &PageSelectTask_attributes);

  /* creation of GuiTask */
  GuiTaskHandle = osThreadNew(Start_GuiTask, NULL, &GuiTask_attributes);

  /* creation of DpsCoreTask */
  DpsCoreTaskHandle = osThreadNew(Start_DpsCoreTask, NULL, &DpsCoreTask_attributes);

  /* creation of IndevDetectTask */
  IndevDetectTaskHandle = osThreadNew(Start_IndevDetectTask, NULL, &IndevDetectTask_attributes);

  /* creation of PIDTask */
  PIDTaskHandle = osThreadNew(Start_PIDTask, NULL, &PIDTask_attributes);

  /* creation of CalibrateTask */
  CalibrateTaskHandle = osThreadNew(Start_CalibrateTask, NULL, &CalibrateTask_attributes);

  /* creation of AwgTask */
  AwgTaskHandle = osThreadNew(Start_AwgTask, NULL, &AwgTask_attributes);

  /* creation of DmmCoreTask */
  DmmCoreTaskHandle = osThreadNew(Start_DmmCoreTask, NULL, &DmmCoreTask_attributes);

  /* creation of PdTask */
  PdTaskHandle = osThreadNew(Start_PdTask, NULL, &PdTask_attributes);

  /* creation of DsoCoreTask */
  DsoCoreTaskHandle = osThreadNew(Start_DsoCoreTask, NULL, &DsoCoreTask_attributes);

  /* creation of SerialCoreTask */
  SerialCoreTaskHandle = osThreadNew(Start_SerialCoreTask, NULL, &SerialCoreTask_attributes);

}

__weak void Start_InitTask(void *argument)
{
  /* init code for USB_DEVICE */
  MX_USB_DEVICE_Init();
  /* USER CODE BEGIN Start_InitTask */
  /* Infinite loop */
  for(;;){
    // 此函数为弱定义，实际定义于Task文件夹内的InitTask中
  }
  /* USER CODE END Start_InitTask */
}
